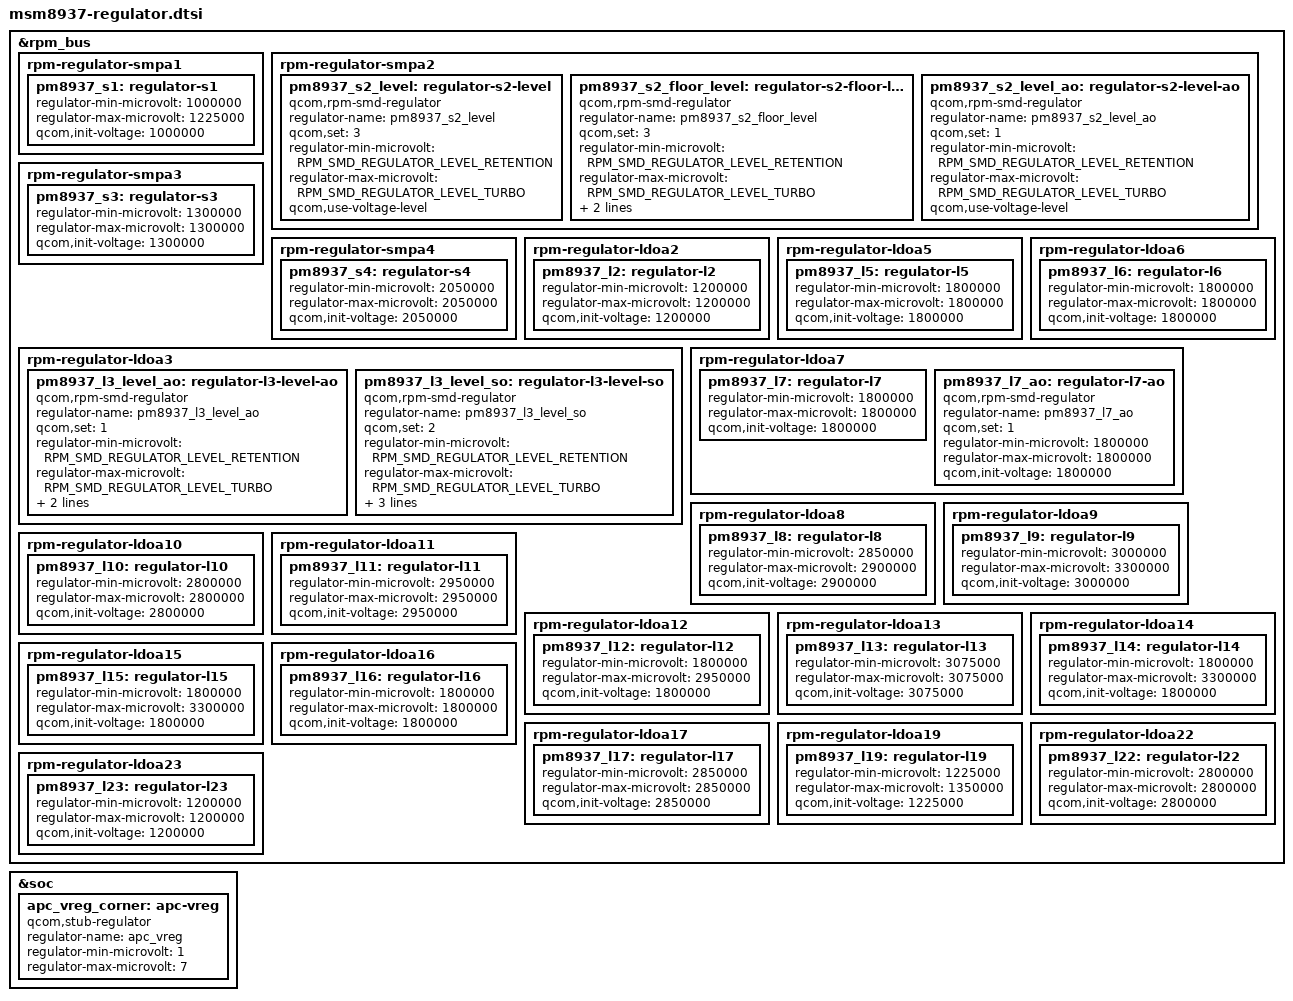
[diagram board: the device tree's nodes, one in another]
/*
 * Copyright (c) 2015, The Linux Foundation. All rights reserved.
 *
 * This program is free software; you can redistribute it and/or modify
 * it under the terms of the GNU General Public License version 2 and
 * only version 2 as published by the Free Software Foundation.
 *
 * This program is distributed in the hope that it will be useful,
 * but WITHOUT ANY WARRANTY; without even the implied warranty of
 * MERCHANTABILITY or FITNESS FOR A PARTICULAR PURPOSE.  See the
 * GNU General Public License for more details.
 */

&rpm_bus {
	rpm-regulator-smpa1 {
		status = "okay";
		pm8937_s1: regulator-s1 {
			regulator-min-microvolt = <1000000>;
			regulator-max-microvolt = <1225000>;
			qcom,init-voltage = <1000000>;
			status = "okay";
		};
	};

	/* VDD_CX supply */
	rpm-regulator-smpa2 {
		status = "okay";
		pm8937_s2_level: regulator-s2-level {
			compatible = "qcom,rpm-smd-regulator";
			regulator-name = "pm8937_s2_level";
			qcom,set = <3>;
			regulator-min-microvolt =
				<RPM_SMD_REGULATOR_LEVEL_RETENTION>;
			regulator-max-microvolt =
				<RPM_SMD_REGULATOR_LEVEL_TURBO>;
			qcom,use-voltage-level;
		};

		pm8937_s2_floor_level: regulator-s2-floor-level {
			compatible = "qcom,rpm-smd-regulator";
			regulator-name = "pm8937_s2_floor_level";
			qcom,set = <3>;
			regulator-min-microvolt =
				<RPM_SMD_REGULATOR_LEVEL_RETENTION>;
			regulator-max-microvolt =
				<RPM_SMD_REGULATOR_LEVEL_TURBO>;
			qcom,use-voltage-floor-level;
			qcom,always-send-voltage;
		};

		pm8937_s2_level_ao: regulator-s2-level-ao {
			compatible = "qcom,rpm-smd-regulator";
			regulator-name = "pm8937_s2_level_ao";
			qcom,set = <1>;
			regulator-min-microvolt =
				<RPM_SMD_REGULATOR_LEVEL_RETENTION>;
			regulator-max-microvolt =
				<RPM_SMD_REGULATOR_LEVEL_TURBO>;
			qcom,use-voltage-level;
		};
	};

	rpm-regulator-smpa3 {
		status = "okay";
		pm8937_s3: regulator-s3 {
			regulator-min-microvolt = <1300000>;
			regulator-max-microvolt = <1300000>;
			qcom,init-voltage = <1300000>;
			status = "okay";
		};
	};

	rpm-regulator-smpa4 {
		status = "okay";
		pm8937_s4: regulator-s4 {
			regulator-min-microvolt = <2050000>;
			regulator-max-microvolt = <2050000>;
			qcom,init-voltage = <2050000>;
			status = "okay";
		};
	};

	rpm-regulator-ldoa2 {
		status = "okay";
		pm8937_l2: regulator-l2 {
			regulator-min-microvolt = <1200000>;
			regulator-max-microvolt = <1200000>;
			qcom,init-voltage = <1200000>;
			status = "okay";
		};
	};

	/* VDD_MX supply */
	rpm-regulator-ldoa3 {
		status = "okay";
		pm8937_l3_level_ao: regulator-l3-level-ao {
			compatible = "qcom,rpm-smd-regulator";
			regulator-name = "pm8937_l3_level_ao";
			qcom,set = <1>;
			regulator-min-microvolt =
				<RPM_SMD_REGULATOR_LEVEL_RETENTION>;
			regulator-max-microvolt =
				<RPM_SMD_REGULATOR_LEVEL_TURBO>;
			qcom,use-voltage-level;
			qcom,always-send-voltage;
		};

		pm8937_l3_level_so: regulator-l3-level-so {
			compatible = "qcom,rpm-smd-regulator";
			regulator-name = "pm8937_l3_level_so";
			qcom,set = <2>;
			regulator-min-microvolt =
				<RPM_SMD_REGULATOR_LEVEL_RETENTION>;
			regulator-max-microvolt =
				<RPM_SMD_REGULATOR_LEVEL_TURBO>;
			qcom,init-voltage-level =
				<RPM_SMD_REGULATOR_LEVEL_RETENTION>;
			qcom,use-voltage-level;
		};
	};

	rpm-regulator-ldoa5 {
		status = "okay";
		pm8937_l5: regulator-l5 {
			regulator-min-microvolt = <1800000>;
			regulator-max-microvolt = <1800000>;
			qcom,init-voltage = <1800000>;
			status = "okay";
		};
	};

	rpm-regulator-ldoa6 {
		status = "okay";
		pm8937_l6: regulator-l6 {
			regulator-min-microvolt = <1800000>;
			regulator-max-microvolt = <1800000>;
			qcom,init-voltage = <1800000>;
			status = "okay";
		};
	};

	rpm-regulator-ldoa7 {
		status = "okay";
		pm8937_l7: regulator-l7 {
			regulator-min-microvolt = <1800000>;
			regulator-max-microvolt = <1800000>;
			qcom,init-voltage = <1800000>;
			status = "okay";
		};

		pm8937_l7_ao: regulator-l7-ao {
			compatible = "qcom,rpm-smd-regulator";
			regulator-name = "pm8937_l7_ao";
			qcom,set = <1>;
			regulator-min-microvolt = <1800000>;
			regulator-max-microvolt = <1800000>;
			qcom,init-voltage = <1800000>;
		};
	};

	rpm-regulator-ldoa8 {
		status = "okay";
		pm8937_l8: regulator-l8 {
			regulator-min-microvolt = <2850000>;
			regulator-max-microvolt = <2900000>;
			qcom,init-voltage = <2900000>;
			status = "okay";
		};
	};

	rpm-regulator-ldoa9 {
		status = "okay";
		pm8937_l9: regulator-l9 {
			regulator-min-microvolt = <3000000>;
			regulator-max-microvolt = <3300000>;
			qcom,init-voltage = <3000000>;
			status = "okay";
		};
	};

	rpm-regulator-ldoa10 {
		status = "okay";
		pm8937_l10: regulator-l10 {
			regulator-min-microvolt = <2800000>;
			regulator-max-microvolt = <2800000>;
			qcom,init-voltage = <2800000>;
			status = "okay";
		};
	};

	rpm-regulator-ldoa11 {
		status = "okay";
		pm8937_l11: regulator-l11 {
			regulator-min-microvolt = <2950000>;
			regulator-max-microvolt = <2950000>;
			qcom,init-voltage = <2950000>;
			status = "okay";
		};
	};

	rpm-regulator-ldoa12 {
		status = "okay";
		pm8937_l12: regulator-l12 {
			regulator-min-microvolt = <1800000>;
			regulator-max-microvolt = <2950000>;
			qcom,init-voltage = <1800000>;
			status = "okay";
		};
	};

	rpm-regulator-ldoa13 {
		status = "okay";
		pm8937_l13: regulator-l13 {
			regulator-min-microvolt = <3075000>;
			regulator-max-microvolt = <3075000>;
			qcom,init-voltage = <3075000>;
			status = "okay";
		};
	};

	rpm-regulator-ldoa14 {
		status = "okay";
		pm8937_l14: regulator-l14 {
			regulator-min-microvolt = <1800000>;
			regulator-max-microvolt = <3300000>;
			qcom,init-voltage = <1800000>;
			status = "okay";
		};
	};

	rpm-regulator-ldoa15 {
		status = "okay";
		pm8937_l15: regulator-l15 {
			regulator-min-microvolt = <1800000>;
			regulator-max-microvolt = <3300000>;
			qcom,init-voltage = <1800000>;
			status = "okay";
		};
	};

	rpm-regulator-ldoa16 {
		status = "okay";
		pm8937_l16: regulator-l16 {
			regulator-min-microvolt = <1800000>;
			regulator-max-microvolt = <1800000>;
			qcom,init-voltage = <1800000>;
			status = "okay";
		};
	};

	rpm-regulator-ldoa17 {
		status = "okay";
		pm8937_l17: regulator-l17 {
			regulator-min-microvolt = <2850000>;
			regulator-max-microvolt = <2850000>;
			qcom,init-voltage = <2850000>;
			status = "okay";
		};
	};

	rpm-regulator-ldoa19 {
		status = "okay";
		pm8937_l19: regulator-l19 {
			regulator-min-microvolt = <1225000>;
			regulator-max-microvolt = <1350000>;
			qcom,init-voltage = <1225000>;
			status = "okay";
		};
	};

	rpm-regulator-ldoa22 {
		status = "okay";
		pm8937_l22: regulator-l22 {
			regulator-min-microvolt = <2800000>;
			regulator-max-microvolt = <2800000>;
			qcom,init-voltage = <2800000>;
			status = "okay";
		};
	};

	rpm-regulator-ldoa23 {
		status = "okay";
		pm8937_l23: regulator-l23 {
			regulator-min-microvolt = <1200000>;
			regulator-max-microvolt = <1200000>;
			qcom,init-voltage = <1200000>;
			status = "okay";
		};
	};
};

&soc {

	/* TODO: move to CPR regulator */
	apc_vreg_corner: apc-vreg {
		compatible = "qcom,stub-regulator";
		regulator-name = "apc_vreg";
		regulator-min-microvolt = <1>;
		regulator-max-microvolt = <7>;
	};
};
